VERSION ""

NS_ :

BS_:

BU_: BMS TESTER

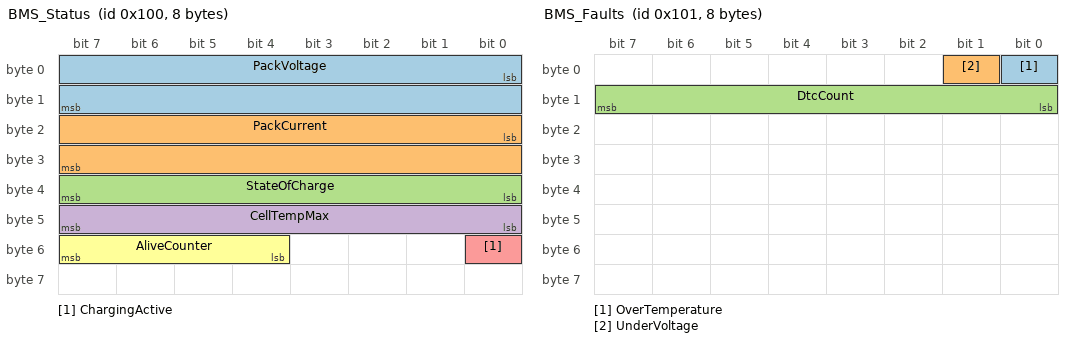
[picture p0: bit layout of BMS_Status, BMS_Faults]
BO_ 256 BMS_Status: 8 BMS
 SG_ PackVoltage : 0|16@1+ (0.1,0) [0|1000] "V" TESTER
 SG_ PackCurrent : 16|16@1- (0.1,0) [-500|500] "A" TESTER
 SG_ StateOfCharge : 32|8@1+ (0.5,0) [0|100] "%" TESTER
 SG_ CellTempMax : 40|8@1+ (1,-40) [-40|125] "degC" TESTER
 SG_ ChargingActive : 48|1@1+ (1,0) [0|1] "" TESTER
 SG_ AliveCounter : 52|4@1+ (1,0) [0|15] "" TESTER

BO_ 257 BMS_Faults: 8 BMS
 SG_ OverTemperature : 0|1@1+ (1,0) [0|1] "" TESTER
 SG_ UnderVoltage : 1|1@1+ (1,0) [0|1] "" TESTER
 SG_ DtcCount : 8|8@1+ (1,0) [0|255] "" TESTER

BO_ 512 Charger_Command: 8 TESTER
 SG_ ChargeEnable : 0|1@1+ (1,0) [0|1] "" BMS
 SG_ TargetCurrent : 8|16@1+ (0.1,0) [0|200] "A" BMS

CM_ BO_ 256 "Zyklischer Status des Batterie-Steuergeraets, Zykluszeit 100 ms";
CM_ BO_ 257 "Fehlerstatus, Zykluszeit 100 ms";
CM_ BO_ 512 "Ladebefehl vom Tester an das BMS";
